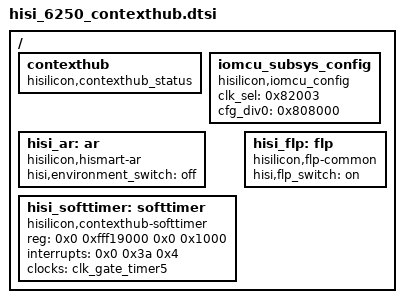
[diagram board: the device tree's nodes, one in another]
/{
    contexthub: contexthub {
        compatible = "hisilicon,contexthub_status";
        status = "ok";
    };
    iomcu_subsys_config {
        compatible = "hisilicon,iomcu_config";
        clk_sel = <0x82003>;
        cfg_div0 = <0x808000>;
    };

    hisi_ar:ar {
        compatible = "hisilicon,hismart-ar";
        status = "ok";
        hisi,environment_switch = "off";    /* on/off */
    };
    hisi_softtimer:softtimer {
        compatible = "hisilicon,contexthub-softtimer";
        status = "ok";
        reg = <0x0 0xfff19000 0x0 0x1000>;
        interrupts = <0x0 0x3a 0x4>;
        clocks = <&clk_gate_timer5>;
        clock-names = "clk_timer5";
    };

    hisi_flp:flp {
        compatible = "hisilicon,flp-common";
        hisi,flp_switch = "on";    /* on/off */
        status = "ok";
    };
};
